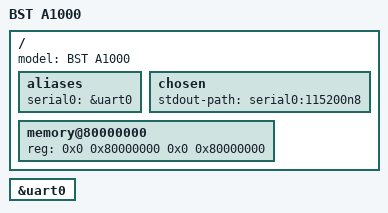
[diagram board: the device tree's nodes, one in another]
/*
 * dts file for Xilinx ZynqMP ep108 development board
 *
 * (C) Copyright 2014 - 2015, Xilinx, Inc.
 *
 * Michal Simek <michal.simek@xilinx.com>
 *
 * This program is free software; you can redistribute it and/or
 * modify it under the terms of the GNU General Public License as
 * published by the Free Software Foundation; either version 2 of
 * the License, or (at your option) any later version.
 */

/dts-v1/;

#include "bsta1000.dtsi"
#include "bsta1000-clk.dtsi"

/ {
	model = "BST A1000";

	aliases {
		serial0 = &uart0;
	};

	chosen {
		stdout-path = "serial0:115200n8";
	};

	memory@80000000 {
		device_type = "memory";
		reg = <0x0 0x80000000 0x0 0x80000000>;
	};
};


&uart0 {
	status = "okay";
};
